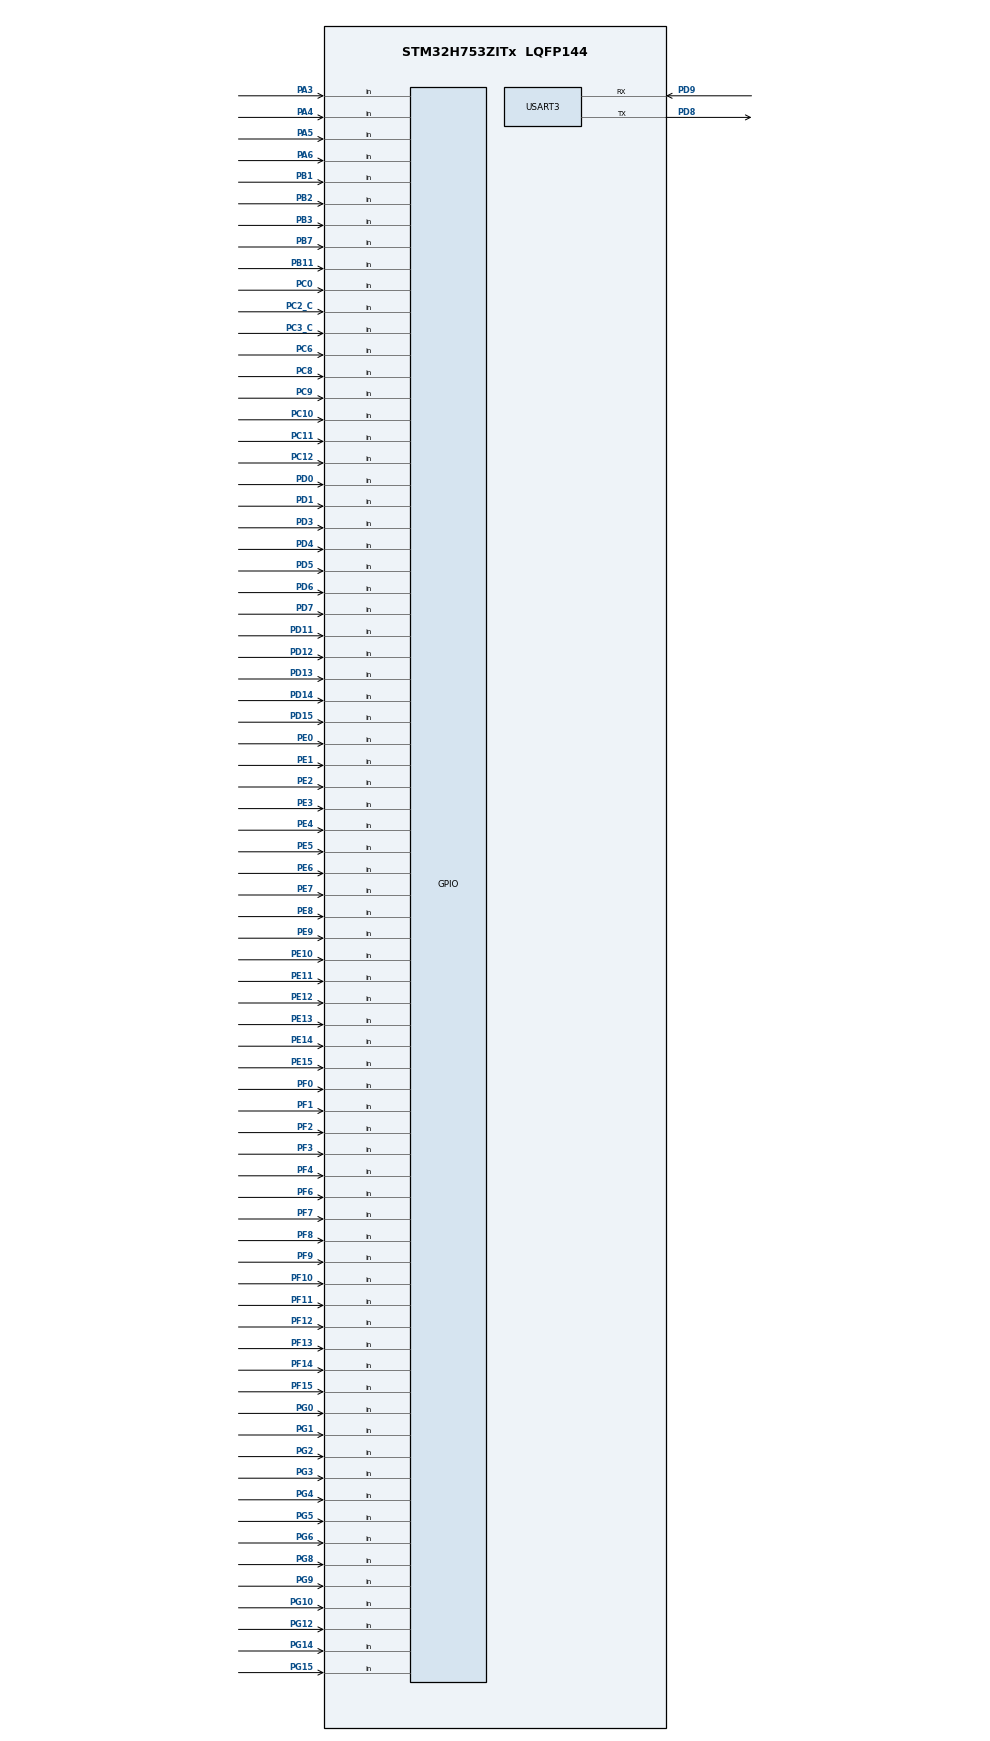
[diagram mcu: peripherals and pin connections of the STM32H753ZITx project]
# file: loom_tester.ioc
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CORTEX_M7.AccessPermission-Cortex_Memory_Protection_Unit_Region0_Settings=MPU_REGION_FULL_ACCESS
CORTEX_M7.BaseAddress-Cortex_Memory_Protection_Unit_Region0_Settings=0x30000000
CORTEX_M7.DisableExec-Cortex_Memory_Protection_Unit_Region0_Settings=MPU_INSTRUCTION_ACCESS_DISABLE
CORTEX_M7.Enable-Cortex_Memory_Protection_Unit_Region0_Settings=MPU_REGION_ENABLE
CORTEX_M7.IsBufferable-Cortex_Memory_Protection_Unit_Region0_Settings=MPU_ACCESS_NOT_BUFFERABLE
CORTEX_M7.IsShareable-Cortex_Memory_Protection_Unit_Region0_Settings=MPU_ACCESS_SHAREABLE
CORTEX_M7.MPU_Control=MPU_PRIVILEGED_DEFAULT
CORTEX_M7.Size-Cortex_Memory_Protection_Unit_Region0_Settings=MPU_REGION_SIZE_512KB
CORTEX_M7.TypeExtField-Cortex_Memory_Protection_Unit_Region0_Settings=MPU_TEX_LEVEL1
Dma.Request0=USART3_RX
Dma.Request1=USART3_TX
Dma.USART3_RX.0.Direction=DMA_PERIPH_TO_MEMORY
Dma.USART3_RX.0.EventEnable=DISABLE
Dma.USART3_RX.0.FIFOMode=DMA_FIFOMODE_DISABLE
Dma.USART3_RX.0.Instance=DMA1_Stream0
Dma.USART3_RX.0.MemDataAlignment=DMA_MDATAALIGN_BYTE
Dma.USART3_RX.0.MemInc=DMA_MINC_ENABLE
Dma.USART3_RX.0.Mode=DMA_NORMAL
Dma.USART3_RX.0.PeriphDataAlignment=DMA_PDATAALIGN_BYTE
Dma.USART3_RX.0.PeriphInc=DMA_PINC_DISABLE
Dma.USART3_RX.0.Polarity=HAL_DMAMUX_REQ_GEN_RISING
Dma.USART3_RX.0.Priority=DMA_PRIORITY_VERY_HIGH
Dma.USART3_RX.0.RequestNumber=1
Dma.USART3_RX.0.SignalID=NONE
Dma.USART3_RX.0.SyncEnable=DISABLE
Dma.USART3_RX.0.SyncPolarity=HAL_DMAMUX_SYNC_NO_EVENT
Dma.USART3_RX.0.SyncRequestNumber=1
Dma.USART3_RX.0.SyncSignalID=NONE
Dma.USART3_TX.1.Direction=DMA_MEMORY_TO_PERIPH
Dma.USART3_TX.1.EventEnable=DISABLE
Dma.USART3_TX.1.FIFOMode=DMA_FIFOMODE_DISABLE
Dma.USART3_TX.1.Instance=DMA1_Stream1
Dma.USART3_TX.1.MemDataAlignment=DMA_MDATAALIGN_BYTE
Dma.USART3_TX.1.MemInc=DMA_MINC_ENABLE
Dma.USART3_TX.1.Mode=DMA_NORMAL
Dma.USART3_TX.1.PeriphDataAlignment=DMA_PDATAALIGN_BYTE
Dma.USART3_TX.1.PeriphInc=DMA_PINC_DISABLE
Dma.USART3_TX.1.Polarity=HAL_DMAMUX_REQ_GEN_RISING
Dma.USART3_TX.1.Priority=DMA_PRIORITY_LOW
Dma.USART3_TX.1.RequestNumber=1
Dma.USART3_TX.1.SignalID=NONE
Dma.USART3_TX.1.SyncEnable=DISABLE
Dma.USART3_TX.1.SyncPolarity=HAL_DMAMUX_SYNC_NO_EVENT
Dma.USART3_TX.1.SyncRequestNumber=1
Dma.USART3_TX.1.SyncSignalID=NONE
Mcu.Family=STM32H7
Mcu.Name=STM32H753ZITx
Mcu.Package=LQFP144
NVIC.DMA1_Stream0_IRQn=true\:0\:0\:false\:false\:true\:false\:true\:true
NVIC.DMA1_Stream1_IRQn=true\:0\:0\:false\:false\:true\:false\:true\:true
NVIC.PriorityGroup=NVIC_PRIORITYGROUP_4
NVIC.USART3_IRQn=true\:0\:0\:false\:false\:true\:true\:true\:true
PA3.GPIO_Mode=GPIO_MODE_INPUT
PA3.GPIO_PuPd=GPIO_PULLDOWN
PA3.Signal=GPIO_Input
PA4.GPIO_Mode=GPIO_MODE_INPUT
PA4.GPIO_PuPd=GPIO_PULLDOWN
PA4.Signal=GPIO_Input
PA5.Signal=GPIO_Input
PA6.Signal=GPIO_Input
PB1.Signal=GPIO_Input
PB11.Signal=GPIO_Input
PB2.Signal=GPIO_Input
PB3\ (JTDO/TRACESWO).GPIO_Mode=GPIO_MODE_INPUT
PB3\ (JTDO/TRACESWO).GPIO_PuPd=GPIO_PULLDOWN
PB3\ (JTDO/TRACESWO).Signal=GPIO_Input
PB7.Signal=GPIO_Input
PC0.GPIO_Mode=GPIO_MODE_INPUT
PC0.GPIO_PuPd=GPIO_PULLDOWN
PC0.Signal=GPIO_Input
PC10.Signal=GPIO_Input
PC11.Signal=GPIO_Input
PC12.Signal=GPIO_Input
PC2_C.Signal=GPIO_Input
PC3_C.Signal=GPIO_Input
PC6.Signal=GPIO_Input
PC8.Signal=GPIO_Input
PC9.Signal=GPIO_Input
PD0.GPIO_PuPd=GPIO_PULLDOWN
PD0.Signal=GPIO_Input
PD1.GPIO_PuPd=GPIO_PULLDOWN
PD1.Signal=GPIO_Input
PD11.GPIO_PuPd=GPIO_PULLDOWN
PD11.Signal=GPIO_Input
PD12.GPIO_PuPd=GPIO_PULLDOWN
PD12.Signal=GPIO_Input
PD13.GPIO_PuPd=GPIO_PULLDOWN
PD13.Signal=GPIO_Input
PD14.GPIO_PuPd=GPIO_PULLDOWN
PD14.Signal=GPIO_Input
PD15.GPIO_PuPd=GPIO_PULLDOWN
PD15.Signal=GPIO_Input
PD3.GPIO_PuPd=GPIO_PULLDOWN
PD3.Signal=GPIO_Input
PD4.GPIO_PuPd=GPIO_PULLDOWN
PD4.Signal=GPIO_Input
PD5.GPIO_PuPd=GPIO_PULLDOWN
PD5.Signal=GPIO_Input
PD6.GPIO_PuPd=GPIO_PULLDOWN
PD6.Signal=GPIO_Input
PD7.GPIO_PuPd=GPIO_PULLDOWN
PD7.Signal=GPIO_Input
PD8.Mode=Asynchronous
PD8.Signal=USART3_TX
PD9.Mode=Asynchronous
PD9.Signal=USART3_RX
PE0.GPIO_PuPd=GPIO_PULLDOWN
PE0.Signal=GPIO_Input
PE1.GPIO_PuPd=GPIO_PULLDOWN
PE1.Signal=GPIO_Input
PE10.GPIO_PuPd=GPIO_PULLDOWN
PE10.Signal=GPIO_Input
PE11.GPIO_PuPd=GPIO_PULLDOWN
PE11.Signal=GPIO_Input
PE12.GPIO_PuPd=GPIO_PULLDOWN
PE12.Signal=GPIO_Input
PE13.GPIO_PuPd=GPIO_PULLDOWN
PE13.Signal=GPIO_Input
PE14.GPIO_PuPd=GPIO_PULLDOWN
PE14.Signal=GPIO_Input
PE15.GPIO_PuPd=GPIO_PULLDOWN
PE15.Signal=GPIO_Input
PE2.GPIO_PuPd=GPIO_PULLDOWN
PE2.Signal=GPIO_Input
PE3.GPIO_PuPd=GPIO_PULLDOWN
PE3.Signal=GPIO_Input
PE4.GPIO_PuPd=GPIO_PULLDOWN
PE4.Signal=GPIO_Input
PE5.GPIO_PuPd=GPIO_PULLDOWN
PE5.Signal=GPIO_Input
PE6.GPIO_PuPd=GPIO_PULLDOWN
PE6.Signal=GPIO_Input
PE7.GPIO_PuPd=GPIO_PULLDOWN
PE7.Signal=GPIO_Input
PE8.Signal=GPIO_Input
PE9.GPIO_PuPd=GPIO_PULLDOWN
PE9.Signal=GPIO_Input
PF0.GPIO_PuPd=GPIO_PULLDOWN
PF0.Signal=GPIO_Input
PF1.GPIO_PuPd=GPIO_PULLDOWN
PF1.Signal=GPIO_Input
PF10.GPIO_PuPd=GPIO_PULLDOWN
PF10.Signal=GPIO_Input
PF11.GPIO_PuPd=GPIO_PULLDOWN
PF11.Signal=GPIO_Input
PF12.GPIO_PuPd=GPIO_PULLDOWN
PF12.Signal=GPIO_Input
PF13.GPIO_PuPd=GPIO_PULLDOWN
PF13.Signal=GPIO_Input
PF14.GPIO_PuPd=GPIO_PULLDOWN
PF14.Signal=GPIO_Input
PF15.GPIO_PuPd=GPIO_PULLDOWN
PF15.Signal=GPIO_Input
PF2.GPIO_PuPd=GPIO_PULLDOWN
PF2.Signal=GPIO_Input
PF3.GPIO_PuPd=GPIO_PULLDOWN
PF3.Signal=GPIO_Input
PF4.Signal=GPIO_Input
PF6.Signal=GPIO_Input
PF7.Signal=GPIO_Input
PF8.GPIO_PuPd=GPIO_PULLDOWN
PF8.Signal=GPIO_Input
PF9.GPIO_PuPd=GPIO_PULLDOWN
PF9.Signal=GPIO_Input
PG0.GPIO_PuPd=GPIO_PULLDOWN
PG0.Signal=GPIO_Input
PG1.GPIO_PuPd=GPIO_PULLDOWN
PG1.Signal=GPIO_Input
PG10.GPIO_PuPd=GPIO_PULLDOWN
PG10.Signal=GPIO_Input
PG12.GPIO_PuPd=GPIO_PULLDOWN
PG12.Signal=GPIO_Input
PG14.GPIO_PuPd=GPIO_PULLDOWN
PG14.Signal=GPIO_Input
PG15.GPIO_PuPd=GPIO_PULLDOWN
PG15.Signal=GPIO_Input
PG2.GPIO_PuPd=GPIO_PULLDOWN
PG2.Signal=GPIO_Input
PG3.GPIO_PuPd=GPIO_PULLDOWN
PG3.Signal=GPIO_Input
PG4.GPIO_PuPd=GPIO_PULLDOWN
PG4.Signal=GPIO_Input
PG5.GPIO_PuPd=GPIO_PULLDOWN
PG5.Signal=GPIO_Input
PG6.GPIO_PuPd=GPIO_PULLDOWN
PG6.Signal=GPIO_Input
PG8.GPIO_PuPd=GPIO_PULLDOWN
PG8.Signal=GPIO_Input
PG9.GPIO_PuPd=GPIO_PULLDOWN
PG9.Signal=GPIO_Input
ProjectManager.HeapSize=0x200
ProjectManager.StackSize=0x400
ProjectManager.TargetToolchain=Makefile
RCC.ADCFreq_Value=129000000
RCC.APB1Freq_Value=32000000
RCC.APB2Freq_Value=64000000
RCC.APB3Freq_Value=64000000
RCC.APB4Freq_Value=64000000
RCC.CortexFreq_Value=64000000
RCC.D2PPRE1=RCC_APB1_DIV2
RCC.HCLKFreq_Value=64000000
RCC.SYSCLKFreq_VALUE=64000000
RCC.USBFreq_Value=129000000
USART3.DMADisableonRxErrorParam=ADVFEATURE_DMA_DISABLEONRXERROR
USART3.OverrunDisableParam=ADVFEATURE_OVERRUN_DISABLE
USART3.VirtualMode-Asynchronous=VM_ASYNC
VP_MEMORYMAP_VS_MEMORYMAP.Mode=CurAppReg
board=custom

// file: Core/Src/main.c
/* USER CODE BEGIN Header */
/**
  ******************************************************************************
  * @file           : main.c
  * @brief          : Main program body
  ******************************************************************************
  * @attention
  *
  * Copyright (c) 2026 STMicroelectronics.
  * All rights reserved.
  *
  * This software is licensed under terms that can be found in the LICENSE file
  * in the root directory of this software component.
  * If no LICENSE file comes with this software, it is provided AS-IS.
  *
  ******************************************************************************
  */
/* USER CODE END Header */
#include "main.h"

/* USER CODE BEGIN Includes */
#include "stm32h7xx_hal_def.h"
#include "stm32h7xx_hal_gpio.h"
#include "stm32h7xx_hal_uart.h"
#include "stm32h7xx_hal_uart_ex.h"
#include "string.h"
#include "stdio.h"
#include <stdint.h>
#include <stdbool.h>
#include <sys/types.h>

/* USER CODE END Includes */

/* USER CODE BEGIN PTD */
typedef struct Pin {
  GPIO_TypeDef* Letter;
  uint16_t Number;
  uint16_t index;
} Pin;

typedef enum State {
  Start,
  Configure_Pins,
  Echo,
  Continue,
  Default,
} State;

/* USER CODE END PTD */

/* USER CODE BEGIN PD */
// #define Debug
/* USER CODE END PD */

UART_HandleTypeDef huart3;
DMA_HandleTypeDef hdma_usart3_rx;
DMA_HandleTypeDef hdma_usart3_tx;

/* USER CODE BEGIN PV */
#define GPIO_PINS_Len 72
Pin Pins[GPIO_PINS_Len] = {
    {.index=0, .Letter = GPIOE, .Number = GPIO_PIN_14},
    {.index=1, .Letter = GPIOE, .Number = GPIO_PIN_15},
    {.index=2, .Letter = GPIOE, .Number = GPIO_PIN_13},
    {.index=3, .Letter = GPIOF, .Number = GPIO_PIN_13},
    {.index=4, .Letter = GPIOF, .Number = GPIO_PIN_12},
    {.index=5, .Letter = GPIOG, .Number = GPIO_PIN_14},
    {.index=6, .Letter = GPIOG, .Number = GPIO_PIN_4},
    {.index=7, .Letter = GPIOG, .Number = GPIO_PIN_6},
    {.index=8, .Letter = GPIOG, .Number = GPIO_PIN_5},
    {.index=9, .Letter = GPIOG, .Number = GPIO_PIN_8},
    {.index=10, .Letter = GPIOE, .Number = GPIO_PIN_0},
    {.index=11, .Letter = GPIOF, .Number = GPIO_PIN_11},
    {.index=12, .Letter = GPIOF, .Number = GPIO_PIN_15},
    {.index=13, .Letter = GPIOF, .Number = GPIO_PIN_3},
    {.index=14, .Letter = GPIOE, .Number = GPIO_PIN_12},
    {.index=15, .Letter = GPIOE, .Number = GPIO_PIN_10},
    {.index=16, .Letter = GPIOD, .Number = GPIO_PIN_11},
    {.index=17, .Letter = GPIOD, .Number = GPIO_PIN_12},
    {.index=18, .Letter = GPIOD, .Number = GPIO_PIN_13},
    {.index=19, .Letter = GPIOA, .Number = GPIO_PIN_3},
    {.index=20, .Letter = GPIOB, .Number = GPIO_PIN_10},
    {.index=21, .Letter = GPIOF, .Number = GPIO_PIN_10},
    {.index=22, .Letter = GPIOE, .Number = GPIO_PIN_7},
    {.index=23, .Letter = GPIOD, .Number = GPIO_PIN_14},
    {.index=24, .Letter = GPIOD, .Number = GPIO_PIN_15},
    {.index=25, .Letter = GPIOF, .Number = GPIO_PIN_14},
    {.index=26, .Letter = GPIOE, .Number = GPIO_PIN_9},
    {.index=27, .Letter = GPIOE, .Number = GPIO_PIN_11},
    {.index=28, .Letter = GPIOE, .Number = GPIO_PIN_5},
    {.index=29, .Letter = GPIOE, .Number = GPIO_PIN_4},
    {.index=30, .Letter = GPIOE, .Number = GPIO_PIN_2},
    {.index=31, .Letter = GPIOG, .Number = GPIO_PIN_3},
    {.index=32, .Letter = GPIOG, .Number = GPIO_PIN_2},
    {.index=33, .Letter = GPIOD, .Number = GPIO_PIN_3},
    {.index=34, .Letter = GPIOC, .Number = GPIO_PIN_0},
    {.index=35, .Letter = GPIOA, .Number = GPIO_PIN_4},
    {.index=36, .Letter = GPIOD, .Number = GPIO_PIN_4},
    {.index=37, .Letter = GPIOD, .Number = GPIO_PIN_5},
    {.index=38, .Letter = GPIOD, .Number = GPIO_PIN_6},
    {.index=39, .Letter = GPIOD, .Number = GPIO_PIN_7},
    {.index=40, .Letter = GPIOE, .Number = GPIO_PIN_3},
    {.index=41, .Letter = GPIOF, .Number = GPIO_PIN_1},
    {.index=42, .Letter = GPIOF, .Number = GPIO_PIN_2},
    {.index=43, .Letter = GPIOF, .Number = GPIO_PIN_8},
    {.index=44, .Letter = GPIOF, .Number = GPIO_PIN_9},
    {.index=45, .Letter = GPIOG, .Number = GPIO_PIN_1},
    {.index=46, .Letter = GPIOE, .Number = GPIO_PIN_6},
    {.index=47, .Letter = GPIOG, .Number = GPIO_PIN_15},
    {.index=48, .Letter = GPIOG, .Number = GPIO_PIN_10},
    {.index=49, .Letter = GPIOG, .Number = GPIO_PIN_12},
    {.index=50, .Letter = GPIOG, .Number = GPIO_PIN_9},
    {.index=51, .Letter = GPIOE, .Number = GPIO_PIN_1},
    {.index=52, .Letter = GPIOG, .Number = GPIO_PIN_0},
    {.index=53, .Letter = GPIOD, .Number = GPIO_PIN_0},
    {.index=54, .Letter = GPIOD, .Number = GPIO_PIN_1},
    {.index=55, .Letter = GPIOF, .Number = GPIO_PIN_0},
    //------------------------------------------------
    {.index=56, .Letter= GPIOA, .Number = GPIO_PIN_6},
    {.index=57, .Letter= GPIOA, .Number = GPIO_PIN_5},
    {.index=58, .Letter= GPIOC, .Number = GPIO_PIN_6},
    {.index=59, .Letter= GPIOB, .Number = GPIO_PIN_11},
    {.index=60, .Letter= GPIOB, .Number = GPIO_PIN_2},
    {.index=61, .Letter= GPIOB, .Number = GPIO_PIN_1},
    {.index=62, .Letter= GPIOF, .Number = GPIO_PIN_4},
    {.index=63, .Letter= GPIOE, .Number = GPIO_PIN_8},
    //------------------------------------------------
    {.index=64, .Letter= GPIOC, .Number = GPIO_PIN_11},
    {.index=65, .Letter= GPIOC, .Number = GPIO_PIN_10},
    {.index=66, .Letter= GPIOC, .Number = GPIO_PIN_12},
    {.index=67, .Letter= GPIOF, .Number = GPIO_PIN_6},
    {.index=68, .Letter= GPIOF, .Number = GPIO_PIN_7},
    {.index=69, .Letter= GPIOB, .Number = GPIO_PIN_7},
    {.index=70, .Letter= GPIOC, .Number = GPIO_PIN_2},
    {.index=71, .Letter= GPIOC, .Number = GPIO_PIN_3},
};

uint8_t Output_Pins_len = 0;
Pin Output_Pins[GPIO_PINS_Len ];
uint8_t Input_Pins_len = 0;
Pin Input_Pins[GPIO_PINS_Len];

#define RX3_BUF_SIZE 256
//uint8_t* rx3_buf = (uint8_t*)0x30000000;
uint8_t rx3_buf[RX3_BUF_SIZE] __attribute__((section(".dma_buffer"), aligned(32)));
volatile uint8_t rx3_len = 0;
volatile uint8_t rx3_offset = 0;
volatile bool rx3_done = false;

#define CONN_MSG_SIZE 256
uint8_t conn_msg[CONN_MSG_SIZE] __attribute__((section(".dma_buffer"), aligned(32)));

/* USER CODE END PV */

void SystemClock_Config(void);
static void MPU_Config(void);
static void MX_GPIO_Init(void);
static void MX_DMA_Init(void);
static void MX_USART3_UART_Init(void);

/* USER CODE BEGIN 0 */
//FF FF FF 1C 01 02 03 04 05 06 07 08 09 0A 0B 0C 0D 0E 0F 10 11 12 13 14 15 16 17 18 19 1A 1B 1C 1D 1E 1F 20 21 22 23 24 25 26 27 28 29 2A 2B 2C 2D 2E 2F 30 31 32 33 34 35 36 37 38
void do_Tx(UART_HandleTypeDef* huart, uint8_t* buf, uint16_t len) {
  while(huart->gState != HAL_UART_STATE_READY) {}
  HAL_UART_Transmit_DMA(huart, buf, len);
}

void set_pin_output(Pin pin) {
  GPIO_InitTypeDef GPIO_InitStruct = {0};
  GPIO_InitStruct.Pin = pin.Number;
  GPIO_InitStruct.Mode = GPIO_MODE_OUTPUT_PP;
  GPIO_InitStruct.Pull = GPIO_NOPULL;
  GPIO_InitStruct.Speed = GPIO_SPEED_FREQ_LOW;
  HAL_GPIO_Init(pin.Letter, &GPIO_InitStruct);
}

void set_pin_input(Pin pin) {
  GPIO_InitTypeDef GPIO_InitStruct = {0};
  GPIO_InitStruct.Pin = pin.Number;
  GPIO_InitStruct.Mode = GPIO_MODE_INPUT;
  GPIO_InitStruct.Pull = GPIO_PULLDOWN;
  GPIO_InitStruct.Speed = GPIO_SPEED_FREQ_LOW;
  HAL_GPIO_Init(pin.Letter, &GPIO_InitStruct);
}

int append_pin_config(uint8_t* confptr, uint8_t len) {
    if(confptr[0] >= len) {
    #ifdef Debug
    do_Tx(&huart3, (uint8_t*)"impossible pin config continue\n", 32);
    #endif
    return 1;
  }

  return 0;

}

int apply_pin_config(uint8_t* confptr, uint8_t len, bool append) {
  if(confptr[0] >= len) {
    #ifdef Debug
    do_Tx(&huart3, (uint8_t*)"impossible pin config\n", 22);
    #endif
    return 1;
  }
  #ifdef Debug
    char conn_unit[4] = "";
    conn_msg[0] = '\0';
  #endif /* if  */
  uint8_t output_count = confptr[0];

  if (!append) {
    Output_Pins_len = 0;
    Input_Pins_len = 0;
  }

  for(uint8_t i = 1; i <= output_count; i++) {
    if (confptr[i] >= GPIO_PINS_Len) {
      #ifdef Debug
        do_Tx(&huart3, (uint8_t*)"undefined pin in config !\n", 26);
      #endif
      return 1;
    }
    Output_Pins[Output_Pins_len] = Pins[confptr[i]];
    #ifdef Debug
      snprintf(conn_unit, 4, "%d,",Output_Pins[Output_Pins_len].index);
      strcat((char*)conn_msg, conn_unit);
    #endif /* ifdef Debug */
    Output_Pins_len++;
  }

  strcat((char*)conn_msg, ":");

  for(uint8_t i = output_count+1; i < len; i++) {
    if (confptr[i] >= GPIO_PINS_Len) {
      #ifdef Debug
        do_Tx(&huart3, (uint8_t*)"undefined pin in config !\n", 26);
      #endif
      return 1;
    }
    Input_Pins[Input_Pins_len] = Pins[confptr[i]];
    #ifdef  Debug
      snprintf(conn_unit, 4, "%d,",Input_Pins[Input_Pins_len].index);
      strcat((char*)conn_msg, conn_unit);
    #endif /* ifdef  DEBUG */
    Input_Pins_len++;
  }
  #ifdef Debug
    strcat((char*)conn_msg, "\n");
  #endif /* ifdef Debug */
  #ifdef Debug
    do_Tx(&huart3, conn_msg, strlen((char*)conn_msg));
  #endif
  return 0;
}

uint8_t* trim_leading(uint8_t thing, uint8_t* org_str, uint16_t* len ) {
  uint8_t* str = org_str;
  while(*str == thing) {str++; (*len)--;}
  return str;
}

int process_ascii_input(char* result, uint8_t size) {
    if(rx3_len <= 1) {
      #ifdef Debug
      do_Tx(&huart3, (uint8_t*)"Input Error (ASCII) !\n", 22);
      #endif
      return 1;
    }

    uint16_t rx3_clean_len = rx3_len;
    uint8_t* rx3_clean_buf = trim_leading(' ',rx3_buf, &rx3_clean_len);

    //do_Tx(&huart3, (uint8_t*)rx3_clean_buf, rx3_clean_len);

    uint8_t copy_len = ((rx3_clean_len) < (size)) ? (rx3_clean_len) : (size );
    strncpy(result, (char*)rx3_clean_buf, copy_len-1);
    result[copy_len-1] = '\0';
    return 0;
}

int process_hex_input(uint8_t* result, uint8_t* size) {
    if(rx3_len <= 1) {
      #ifdef Debug
      do_Tx(&huart3, (uint8_t*)"Input Error (HEX) !\n", 20) ;
      #endif
      return 1;
    }

    uint16_t rx3_clean_len = rx3_len;
    uint8_t* rx3_clean_buf = trim_leading(0xFF, rx3_buf, &rx3_clean_len);

    //do_Tx(&huart3, (uint8_t*)rx3_clean_buf, rx3_clean_len); //Since HEX, provides WIERD ASCII

    memset(result,0,*size);
    uint8_t copy_len = ((rx3_clean_len) < (*size)) ? (rx3_clean_len) : (*size);
    memcpy(result, rx3_clean_buf, copy_len);
    *size = copy_len;
    return 0;
}

/* USER CODE END 0 */

int main(void)
{

  /* MPU Configuration--------------------------------------------------------*/
  MPU_Config();

  /* MCU Configuration--------------------------------------------------------*/

  /* Reset of all peripherals, Initializes the Flash interface and the Systick. */
  HAL_Init();

  /* Configure the system clock */
  SystemClock_Config();

  /* Initialize all configured peripherals */
  MX_GPIO_Init();
  MX_DMA_Init();
  MX_USART3_UART_Init();
  /* USER CODE BEGIN 2 */
  State state = Default;
  bool append = false;
  HAL_UART_Transmit_DMA(&huart3, (uint8_t*)"Startup...\n", 11);
  HAL_UARTEx_ReceiveToIdle_DMA(&huart3, rx3_buf, RX3_BUF_SIZE);
  for(int i = 0; i < GPIO_PINS_Len; i++) {
    set_pin_input(Pins[i]);
  }
  /* USER CODE END 2 */

  /* Infinite loop */
  /* USER CODE BEGIN WHILE */
  while (1)
  {
    switch (state) {
      case Default:
        while(1) {
          if(rx3_done == true) {
            rx3_done = false;
            #ifdef Debug
            do_Tx(&huart3, rx3_buf, rx3_len);
            #endif /* ifdef Debug */
            #define CMD_SIZE 5
            char cmd[CMD_SIZE];
            if (process_ascii_input(cmd,CMD_SIZE) != 0)
              break;

            if (strcmp(cmd,"go") == 0) {
              state = Start;
              break;
            }
            else if(strcmp(cmd,"conf") == 0) {
              state = Configure_Pins;
              break;
            }
            else if(strcmp(cmd,"cont") == 0) {
              state = Continue;
              break;
            }
            else
             break;
          }
        }
      break;

      case Echo:
        while(1) {
          if (rx3_done == true) {
            rx3_done = false;
            do_Tx(&huart3, rx3_buf, rx3_len);
            HAL_Delay(50);
          }
        }
      break;

      case Configure_Pins:
        #ifdef Debug
        do_Tx(&huart3, (uint8_t*)"Config Pins\n", 12);
        #endif /* ifdef Debug */
        do_Tx(&huart3, (uint8_t*)"conf ACK\n",9);
        while(1) {
          if(rx3_done == true) {
            rx3_done = false;
            uint8_t config_size = 64;
            uint8_t config_data[config_size];
            if (process_hex_input(config_data, &config_size) != 0)
              break;
            if (apply_pin_config(config_data, config_size, append) != 0)
              break;
            #ifdef Debug
            do_Tx(&huart3, (uint8_t*)"Config Successfull\n", 19);
            #endif
            do_Tx(&huart3, (uint8_t*)"ACK\n",4);
            state = Default;
            append = false;
            break;
          }
        }

      break;
      case Continue:
        do_Tx(&huart3, (uint8_t*)"cont ACK\n",9);
        append = true;
        state = Configure_Pins;
      break;
      case Start:
          #ifdef Debug
          do_Tx(&huart3, (uint8_t*)"Run Check\n", 10);
          #endif
          if (Output_Pins_len < 1 || Input_Pins_len < 1) {
              #ifdef Debug
              do_Tx(&huart3, (uint8_t*)"Pins not configured\n", 21);
              #endif /* ifdef Debug */
              do_Tx(&huart3, (uint8_t*)"go NACK\n", 8);
              state = Default;
              break;
          }
          conn_msg[0] = '\0';
          char conn_unit[7];

          for(uint8_t i = 0; i < Output_Pins_len; i++) {
            set_pin_output(Output_Pins[i]);
            HAL_GPIO_WritePin(Output_Pins[i].Letter, Output_Pins[i].Number, GPIO_PIN_SET);
            sprintf(conn_unit, "%d:", Output_Pins[i].index);
            strcat((char*)conn_msg,conn_unit);

            for(int k = 0; k < GPIO_PINS_Len; k++) {
              if ((HAL_GPIO_ReadPin(Pins[k].Letter, Pins[k].Number) == GPIO_PIN_SET) && (Pins[k].index != Output_Pins[i].index)) {
                sprintf(conn_unit, "%d,", Pins[k].index);
                strcat((char*)conn_msg,conn_unit);
              }
            }

            HAL_GPIO_WritePin(Output_Pins[i].Letter, Output_Pins[i].Number, GPIO_PIN_RESET);
            set_pin_input(Output_Pins[i]);
            strcat((char*)conn_msg,"\n");
          }
          do_Tx(&huart3, conn_msg, strlen((char*)conn_msg));
          do_Tx(&huart3, (uint8_t*)"go ACK\n",7);
          state = Default;
      break;
    }
    /* USER CODE END WHILE */

  }
}

void SystemClock_Config(void)
{
  RCC_OscInitTypeDef RCC_OscInitStruct = {0};
  RCC_ClkInitTypeDef RCC_ClkInitStruct = {0};

  /** Supply configuration update enable
  */
  HAL_PWREx_ConfigSupply(PWR_LDO_SUPPLY);

  /** Configure the main internal regulator output voltage
  */
  __HAL_PWR_VOLTAGESCALING_CONFIG(PWR_REGULATOR_VOLTAGE_SCALE3);

  while(!__HAL_PWR_GET_FLAG(PWR_FLAG_VOSRDY)) {}

  /** Initializes the RCC Oscillators according to the specified parameters
  * in the RCC_OscInitTypeDef structure.
  */
  RCC_OscInitStruct.OscillatorType = RCC_OSCILLATORTYPE_HSI;
  RCC_OscInitStruct.HSIState = RCC_HSI_DIV1;
  RCC_OscInitStruct.HSICalibrationValue = RCC_HSICALIBRATION_DEFAULT;
  RCC_OscInitStruct.PLL.PLLState = RCC_PLL_NONE;
  if (HAL_RCC_OscConfig(&RCC_OscInitStruct) != HAL_OK)
  {
    Error_Handler();
  }

  /** Initializes the CPU, AHB and APB buses clocks
  */
  RCC_ClkInitStruct.ClockType = RCC_CLOCKTYPE_HCLK|RCC_CLOCKTYPE_SYSCLK
                              |RCC_CLOCKTYPE_PCLK1|RCC_CLOCKTYPE_PCLK2
                              |RCC_CLOCKTYPE_D3PCLK1|RCC_CLOCKTYPE_D1PCLK1;
  RCC_ClkInitStruct.SYSCLKSource = RCC_SYSCLKSOURCE_HSI;
  RCC_ClkInitStruct.SYSCLKDivider = RCC_SYSCLK_DIV1;
  RCC_ClkInitStruct.AHBCLKDivider = RCC_HCLK_DIV1;
  RCC_ClkInitStruct.APB3CLKDivider = RCC_APB3_DIV1;
  RCC_ClkInitStruct.APB1CLKDivider = RCC_APB1_DIV2;
  RCC_ClkInitStruct.APB2CLKDivider = RCC_APB2_DIV1;
  RCC_ClkInitStruct.APB4CLKDivider = RCC_APB4_DIV1;

  if (HAL_RCC_ClockConfig(&RCC_ClkInitStruct, FLASH_LATENCY_1) != HAL_OK)
  {
    Error_Handler();
  }
}

static void MX_USART3_UART_Init(void)
{

  huart3.Instance = USART3;
  huart3.Init.BaudRate = 115200;
  huart3.Init.WordLength = UART_WORDLENGTH_8B;
  huart3.Init.StopBits = UART_STOPBITS_1;
  huart3.Init.Parity = UART_PARITY_NONE;
  huart3.Init.Mode = UART_MODE_TX_RX;
  huart3.Init.HwFlowCtl = UART_HWCONTROL_NONE;
  huart3.Init.OverSampling = UART_OVERSAMPLING_16;
  huart3.Init.OneBitSampling = UART_ONE_BIT_SAMPLE_DISABLE;
  huart3.Init.ClockPrescaler = UART_PRESCALER_DIV1;
  huart3.AdvancedInit.AdvFeatureInit = UART_ADVFEATURE_RXOVERRUNDISABLE_INIT|UART_ADVFEATURE_DMADISABLEONERROR_INIT;
  huart3.AdvancedInit.OverrunDisable = UART_ADVFEATURE_OVERRUN_DISABLE;
  huart3.AdvancedInit.DMADisableonRxError = UART_ADVFEATURE_DMA_DISABLEONRXERROR;
  if (HAL_UART_Init(&huart3) != HAL_OK)
  {
    Error_Handler();
  }
  if (HAL_UARTEx_SetTxFifoThreshold(&huart3, UART_TXFIFO_THRESHOLD_1_8) != HAL_OK)
  {
    Error_Handler();
  }
  if (HAL_UARTEx_SetRxFifoThreshold(&huart3, UART_RXFIFO_THRESHOLD_1_8) != HAL_OK)
  {
    Error_Handler();
  }
  if (HAL_UARTEx_DisableFifoMode(&huart3) != HAL_OK)
  {
    Error_Handler();
  }

}

static void MX_DMA_Init(void)
{

  /* DMA controller clock enable */
  __HAL_RCC_DMA1_CLK_ENABLE();

  /* DMA interrupt init */
  /* DMA1_Stream0_IRQn interrupt configuration */
  HAL_NVIC_SetPriority(DMA1_Stream0_IRQn, 0, 0);
  HAL_NVIC_EnableIRQ(DMA1_Stream0_IRQn);
  /* DMA1_Stream1_IRQn interrupt configuration */
  HAL_NVIC_SetPriority(DMA1_Stream1_IRQn, 0, 0);
  HAL_NVIC_EnableIRQ(DMA1_Stream1_IRQn);

}

static void MX_GPIO_Init(void)
{
  GPIO_InitTypeDef GPIO_InitStruct = {0};

  /* GPIO Ports Clock Enable */
  __HAL_RCC_GPIOE_CLK_ENABLE();
  __HAL_RCC_GPIOF_CLK_ENABLE();
  __HAL_RCC_GPIOC_CLK_ENABLE();
  __HAL_RCC_GPIOA_CLK_ENABLE();
  __HAL_RCC_GPIOB_CLK_ENABLE();
  __HAL_RCC_GPIOG_CLK_ENABLE();
  __HAL_RCC_GPIOD_CLK_ENABLE();

  /*Configure GPIO pins : PE2 PE3 PE4 PE5
                           PE6 PE7 PE9 PE10
                           PE11 PE12 PE13 PE14
                           PE15 PE0 PE1 */
  GPIO_InitStruct.Pin = GPIO_PIN_2|GPIO_PIN_3|GPIO_PIN_4|GPIO_PIN_5
                          |GPIO_PIN_6|GPIO_PIN_7|GPIO_PIN_9|GPIO_PIN_10
                          |GPIO_PIN_11|GPIO_PIN_12|GPIO_PIN_13|GPIO_PIN_14
                          |GPIO_PIN_15|GPIO_PIN_0|GPIO_PIN_1;
  GPIO_InitStruct.Mode = GPIO_MODE_INPUT;
  GPIO_InitStruct.Pull = GPIO_PULLDOWN;
  HAL_GPIO_Init(GPIOE, &GPIO_InitStruct);

  /*Configure GPIO pins : PF0 PF1 PF2 PF3
                           PF8 PF9 PF10 PF11
                           PF12 PF13 PF14 PF15 */
  GPIO_InitStruct.Pin = GPIO_PIN_0|GPIO_PIN_1|GPIO_PIN_2|GPIO_PIN_3
                          |GPIO_PIN_8|GPIO_PIN_9|GPIO_PIN_10|GPIO_PIN_11
                          |GPIO_PIN_12|GPIO_PIN_13|GPIO_PIN_14|GPIO_PIN_15;
  GPIO_InitStruct.Mode = GPIO_MODE_INPUT;
  GPIO_InitStruct.Pull = GPIO_PULLDOWN;
  HAL_GPIO_Init(GPIOF, &GPIO_InitStruct);

  /*Configure GPIO pins : PF4 PF6 PF7 */
  GPIO_InitStruct.Pin = GPIO_PIN_4|GPIO_PIN_6|GPIO_PIN_7;
  GPIO_InitStruct.Mode = GPIO_MODE_INPUT;
  GPIO_InitStruct.Pull = GPIO_NOPULL;
  HAL_GPIO_Init(GPIOF, &GPIO_InitStruct);

  /*Configure GPIO pin : PC0 */
  GPIO_InitStruct.Pin = GPIO_PIN_0;
  GPIO_InitStruct.Mode = GPIO_MODE_INPUT;
  GPIO_InitStruct.Pull = GPIO_PULLDOWN;
  HAL_GPIO_Init(GPIOC, &GPIO_InitStruct);

  /*Configure GPIO pins : PC2 PC3 PC6 PC8
                           PC9 PC10 PC11 PC12 */
  GPIO_InitStruct.Pin = GPIO_PIN_2|GPIO_PIN_3|GPIO_PIN_6|GPIO_PIN_8
                          |GPIO_PIN_9|GPIO_PIN_10|GPIO_PIN_11|GPIO_PIN_12;
  GPIO_InitStruct.Mode = GPIO_MODE_INPUT;
  GPIO_InitStruct.Pull = GPIO_NOPULL;
  HAL_GPIO_Init(GPIOC, &GPIO_InitStruct);

  /*Configure GPIO pins : PA3 PA4 */
  GPIO_InitStruct.Pin = GPIO_PIN_3|GPIO_PIN_4;
  GPIO_InitStruct.Mode = GPIO_MODE_INPUT;
  GPIO_InitStruct.Pull = GPIO_PULLDOWN;
  HAL_GPIO_Init(GPIOA, &GPIO_InitStruct);

  /*Configure GPIO pins : PA5 PA6 */
  GPIO_InitStruct.Pin = GPIO_PIN_5|GPIO_PIN_6;
  GPIO_InitStruct.Mode = GPIO_MODE_INPUT;
  GPIO_InitStruct.Pull = GPIO_NOPULL;
  HAL_GPIO_Init(GPIOA, &GPIO_InitStruct);

  /*Configure GPIO pins : PB1 PB2 PB11 PB7 */
  GPIO_InitStruct.Pin = GPIO_PIN_1|GPIO_PIN_2|GPIO_PIN_11|GPIO_PIN_7;
  GPIO_InitStruct.Mode = GPIO_MODE_INPUT;
  GPIO_InitStruct.Pull = GPIO_NOPULL;
  HAL_GPIO_Init(GPIOB, &GPIO_InitStruct);

  /*Configure GPIO pins : PG0 PG1 PG2 PG3
                           PG4 PG5 PG6 PG8
                           PG9 PG10 PG12 PG14
                           PG15 */
  GPIO_InitStruct.Pin = GPIO_PIN_0|GPIO_PIN_1|GPIO_PIN_2|GPIO_PIN_3
                          |GPIO_PIN_4|GPIO_PIN_5|GPIO_PIN_6|GPIO_PIN_8
                          |GPIO_PIN_9|GPIO_PIN_10|GPIO_PIN_12|GPIO_PIN_14
                          |GPIO_PIN_15;
  GPIO_InitStruct.Mode = GPIO_MODE_INPUT;
  GPIO_InitStruct.Pull = GPIO_PULLDOWN;
  HAL_GPIO_Init(GPIOG, &GPIO_InitStruct);

  /*Configure GPIO pin : PE8 */
  GPIO_InitStruct.Pin = GPIO_PIN_8;
  GPIO_InitStruct.Mode = GPIO_MODE_INPUT;
  GPIO_InitStruct.Pull = GPIO_NOPULL;
  HAL_GPIO_Init(GPIOE, &GPIO_InitStruct);

  /*Configure GPIO pins : PD11 PD12 PD13 PD14
                           PD15 PD0 PD1 PD3
                           PD4 PD5 PD6 PD7 */
  GPIO_InitStruct.Pin = GPIO_PIN_11|GPIO_PIN_12|GPIO_PIN_13|GPIO_PIN_14
                          |GPIO_PIN_15|GPIO_PIN_0|GPIO_PIN_1|GPIO_PIN_3
                          |GPIO_PIN_4|GPIO_PIN_5|GPIO_PIN_6|GPIO_PIN_7;
  GPIO_InitStruct.Mode = GPIO_MODE_INPUT;
  GPIO_InitStruct.Pull = GPIO_PULLDOWN;
  HAL_GPIO_Init(GPIOD, &GPIO_InitStruct);

  /*Configure GPIO pin : PB3 */
  GPIO_InitStruct.Pin = GPIO_PIN_3;
  GPIO_InitStruct.Mode = GPIO_MODE_INPUT;
  GPIO_InitStruct.Pull = GPIO_PULLDOWN;
  HAL_GPIO_Init(GPIOB, &GPIO_InitStruct);

}

/* USER CODE BEGIN 4 */
void HAL_UARTEx_RxEventCallback(UART_HandleTypeDef *huart, uint16_t Size)
{
    if (huart->Instance == USART3)
    {
        //HAL_UART_RxEventTypeTypeDef event_type = HAL_UARTEx_GetRxEventType(huart);
        //if (event_type == HAL_UART_RXEVENT_IDLE) {
          //SCB_InvalidateDCache_by_Addr((uint32_t*)rx3_buf, RX3_BUF_SIZE);
          rx3_len = Size;
          rx3_done = true;
          HAL_UARTEx_ReceiveToIdle_DMA(&huart3, rx3_buf, RX3_BUF_SIZE);
        //}
    }
}

void HAL_UART_ErrorCallback(UART_HandleTypeDef *huart)
{
    if (huart->Instance == huart3.Instance)
    {
        uint32_t err = huart->ErrorCode;
          if (err & (HAL_UART_ERROR_ORE | HAL_UART_ERROR_NE | HAL_UART_ERROR_FE | HAL_UART_ERROR_PE)) {
              HAL_UART_AbortReceive(huart);
              __HAL_UART_SEND_REQ(huart, UART_RXDATA_FLUSH_REQUEST);
              __HAL_UART_CLEAR_FLAG(huart, UART_CLEAR_OREF | UART_CLEAR_NEF | UART_CLEAR_FEF | UART_CLEAR_PEF);
              memset(rx3_buf, 0, RX3_BUF_SIZE);
              HAL_UARTEx_ReceiveToIdle_DMA(huart, rx3_buf, RX3_BUF_SIZE);
          }
    }
}
/* USER CODE END 4 */

 /* MPU Configuration */

void MPU_Config(void)
{
  MPU_Region_InitTypeDef MPU_InitStruct = {0};

  /* Disables the MPU */
  HAL_MPU_Disable();

  /** Initializes and configures the Region and the memory to be protected
  */
  MPU_InitStruct.Enable = MPU_REGION_ENABLE;
  MPU_InitStruct.Number = MPU_REGION_NUMBER0;
  MPU_InitStruct.BaseAddress = 0x30000000;
  MPU_InitStruct.Size = MPU_REGION_SIZE_512KB;
  MPU_InitStruct.SubRegionDisable = 0x0;
  MPU_InitStruct.TypeExtField = MPU_TEX_LEVEL1;
  MPU_InitStruct.AccessPermission = MPU_REGION_FULL_ACCESS;
  MPU_InitStruct.DisableExec = MPU_INSTRUCTION_ACCESS_DISABLE;
  MPU_InitStruct.IsShareable = MPU_ACCESS_SHAREABLE;
  MPU_InitStruct.IsCacheable = MPU_ACCESS_NOT_CACHEABLE;
  MPU_InitStruct.IsBufferable = MPU_ACCESS_NOT_BUFFERABLE;

  HAL_MPU_ConfigRegion(&MPU_InitStruct);
  /* Enables the MPU */
  HAL_MPU_Enable(MPU_PRIVILEGED_DEFAULT);

}

void Error_Handler(void)
{
  __disable_irq();
  while (1)
  {
  }
}
